# LKS32MC07x register map
Vendor: Linko Ltd.; Series: LKS32MC07x; File version: 1.0
CPU: CM0 r1p0, little endian, MPU, no FPU, 3 interrupt priority bits
Registers are 32-bit, read-write, reset 0x0 unless marked. A register's access mark holds for its fields unless they carry their own. Offsets are from the block's base; [hi:lo] are bit positions; {n}, {i} and the like mark numbered series; 'fields as' and 'values as' point back to an identical list.

## QEP0 — QEP0 registers
Base 0x40010A00
Same registers: QEP1 0x40010B00
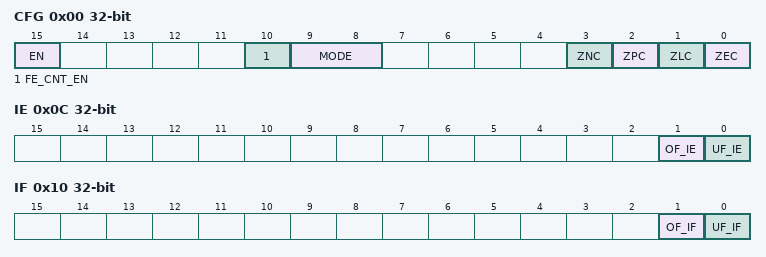
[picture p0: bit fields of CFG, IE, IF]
0x00 CFG — QEP Configuration
  [15] EN — QEP Module Enable
    0=DISABLED (Module Disabled); 1=ENABLED (Module Enabled)
  [10] FE_CNT_EN — Count at falling edge enable
    0=DISABLED (Do not count at falling edge); 1=ENABLED (Counting at falling edge)
  [9:8] MODE — Encoder mode
    0=CT1 (Counting on T1); 1=CT1T2 (Counting on T1 and T2); 2=CCW_SIGN; 3=CCW_CW
  [3] ZNC — Z Signal Clear at low/falling edge enable
    0=DISABLED (Low level/falling edge clear disabled); 1=ENABLED (Low level/falling edge clear enabled)
  [2] ZPC — Z Signal Clear at low/falling edge enable
    0=DISABLED (High level/rising edge clear disabled); 1=ENABLED (High level/rising edge clear enabled)
  [1] ZLC — Z Signal Clear by level enable
    0=DISABLED (Active level clear disabled); 1=ENABLED (Active level clear enabled)
  [0] ZEC — Z Signal Clear by edge enable
    0=DISABLED (Active edge clear disabled); 1=ENABLED (Active edge clear enabled)
0x04 TH — Encoder counter threshold. Encoder will count from 0 to TH, then over again, or from TH down to 0 and over again
  [15:0] TH — Counter threshold
0x08 CNT — Encoder current counter value
  [15:0] CNT — Current counter
0x0C IE — QEP Interrupt Enable
  [1] OF_IE — Overflow Interrupt Enable
    0=DISABLED (Overflow interrupt disabled); 1=ENABLED (Overflow Interrupt enabled)
  [0] UF_IE — Underflow Interrupt Enable
    0=DISABLED (Underflow interrupt disabled); 1=ENABLED (Underflow Interrupt enabled)
0x10 IF — QEP Interrupt Flag
  [1] OF_IF — Overflow Interrupt Flag
  [0] UF_IF — Underflow Interrupt Flag

## GPIO0 — GPIO0 registers
Base 0x40010D00
0x00 PIE — GPIO0 input enable
  [15:0] PIE — GPIO0[n] input enable
0x04 POE — GPIO0 output enable
  [15:0] POE — GPIO0[n] output enable
0x08 PDI — GPIO0 input data
  [15:0] PDI — GPIO0[n] input data
0x0C PDO — GPIO0 output data
  [15:0] PDO — GPIO0[n] output data
0x10 PUE — GPIO0 pull-up enable
  [15:0] PUE — GPIO0[n] pull-up enable
0x18 PODE — GPIO0 open drain enable
  [15:0] PODE — GPIO0[n] open drain enable
0x1C PFLT — GPIO0 filter enable
  [15:0] PFLT — GPIO0[n] filter enable
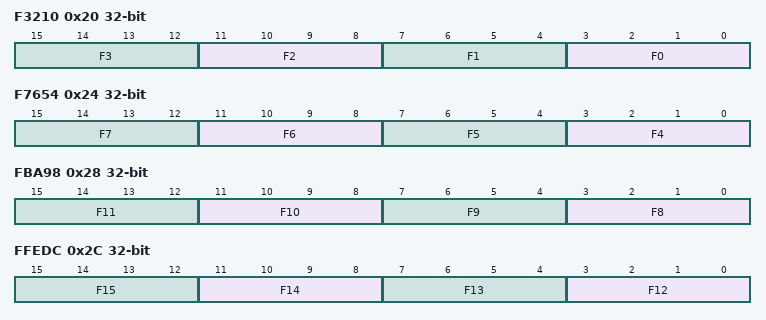
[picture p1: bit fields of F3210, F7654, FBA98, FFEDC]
0x20 F3210 — GPIO0[3:0] function selection
  [all] fields
    0=ANALOG (GPIO function is Analog); 1=SYS (GPIO function is SYS); 2=HALL (GPIO function is HALL); 3=MCPWM (GPIO function is MCPWM); 4=UART (GPIO function is UART0/1); 5=SPI (GPIO function is SPI); 6=I2C (GPIO function is I2C); 7=TIMER0_1 (GPIO function is TIMER0_1); 8=TIMER2_3 (GPIO function is TIMER2_3); 9=DEBUG (GPIO function is ADC_trigger); 10=CAN (GPIO function is CAN); 11=SIF (GPIO function is SIF); 12=CL (GPIO function is CL)
  [4n+3:4n] F{n} (n=0..3) — GPIO0[{n}] function selection
0x24 F7654 — GPIO0[7:4] function selection
  [all] fields
    values as the fields of F3210
  [4n-13:4n-16] F{n} (n=4..7) — GPIO0[{n}] function selection
0x28 FBA98 — GPIO0[11:8] function selection
  [all] fields
    values as the fields of F3210
  [4n-29:4n-32] F{n} (n=8..11) — GPIO0[{n}] function selection
0x2C FFEDC — GPIO0[15:12] function selection
  [all] fields
    values as the fields of F3210
  [4n-45:4n-48] F{n} (n=12..15) — GPIO0[{n-12}] function selection
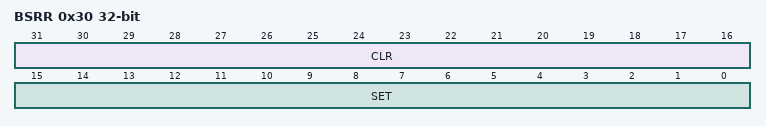
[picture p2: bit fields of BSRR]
0x30 BSRR wo — GPIO0 bit set reset reg
  [31:16] CLR — GPIO0[n] write 1 to clear
  [15:0] SET — GPIO0[n] write 1 to set
0x34 BRR wo — GPIO0 bit reset reg
  [15:0] CLR — GPIO0[n] write 1 to clear

## GPIO1 — GPIO1 registers
Base 0x40010D40
Registers as GPIO0 (with GPIO0 read as GPIO1).

## GPIO2 — GPIO2 registers
Base 0x40010D80
Registers as GPIO0 (with GPIO0 read as GPIO2).

## GPIO3 — GPIO3 registers
Base 0x40010DC0
Registers as GPIO0 (with GPIO0 read as GPIO3).
